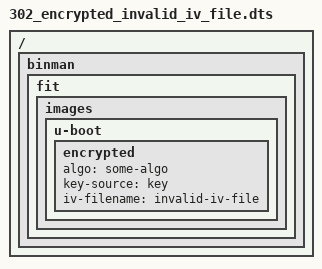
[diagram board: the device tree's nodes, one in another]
// SPDX-License-Identifier: GPL-2.0+
/dts-v1/;

/ {
	binman {
		fit {
			images {
				u-boot {
					encrypted {
						algo = "some-algo";
						key-source = "key";
						iv-filename = "invalid-iv-file";
					};
				};
			};
		};
	};
};
